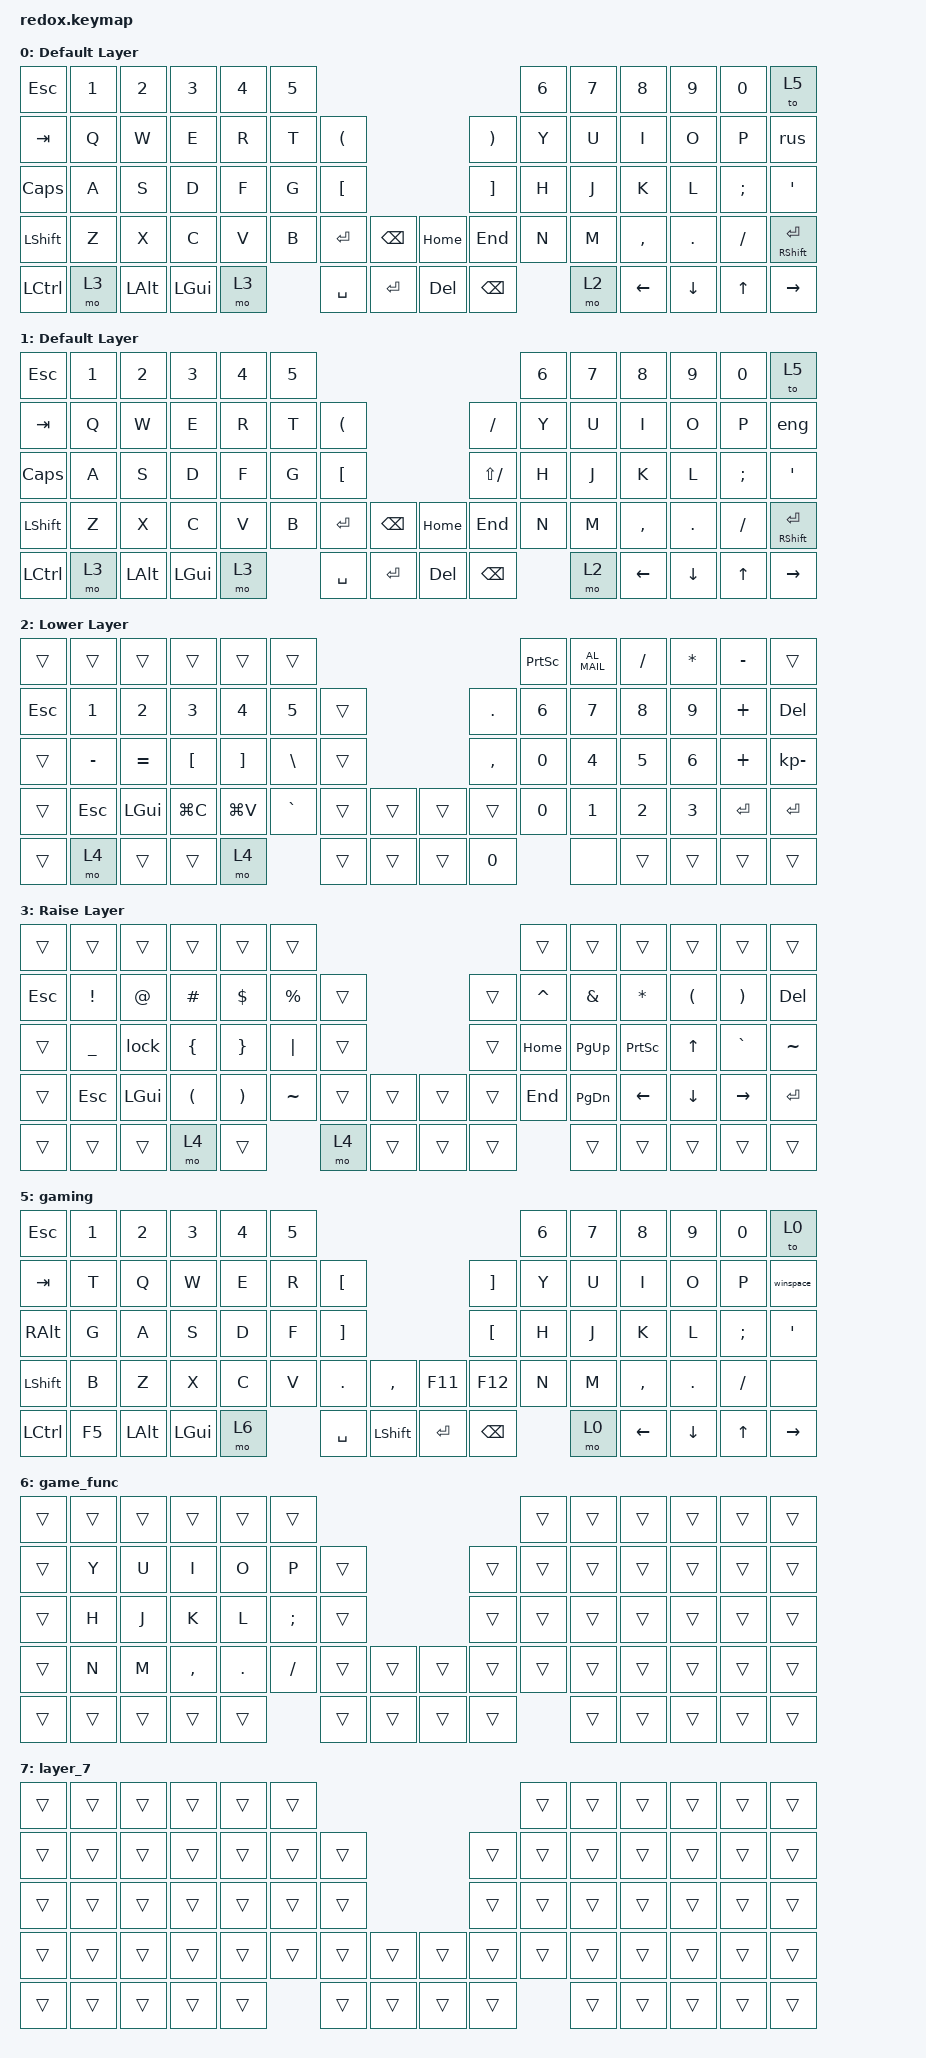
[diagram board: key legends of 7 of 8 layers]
/*
 * Copyright (c) 2021 The ZMK Contributors
 *
 * SPDX-License-Identifier: MIT
 */

#include <behaviors.dtsi>
#include <dt-bindings/zmk/bt.h>
#include <dt-bindings/zmk/keys.h>
#include <dt-bindings/zmk/outputs.h>

/ {
    sensors {
        compatible = "zmk,keymap-sensors";
        sensors = <&left_encoder &right_encoder>;
    };

    left_encoder: encoder_left {
        compatible = "alps,ec11";
        a-gpios = <&gpio1 1 (GPIO_ACTIVE_HIGH | GPIO_PULL_UP)>;
        b-gpios = <&gpio1 2 (GPIO_ACTIVE_HIGH | GPIO_PULL_UP)>;
        steps = <74>;
        status = "okay";
    };

    right_encoder: encoder_right {
        compatible = "alps,ec11";
        a-gpios = <&gpio0 24 (GPIO_ACTIVE_HIGH | GPIO_PULL_UP)>;
        b-gpios = <&gpio0 20 (GPIO_ACTIVE_HIGH | GPIO_PULL_UP)>;
        steps = <7>;
        status = "okay";
    };

    macros {
        rus: language {
            compatible = "zmk,behavior-macro";
            #binding-cells = <0>;
            bindings = <&kp LG(SPACE) &to 1>;
            label = "LANGUAGE";
        };

        eng: eng {
            compatible = "zmk,behavior-macro";
            #binding-cells = <0>;
            bindings = <&kp LG(SPACE) &to 0>;
            label = "ENG";
        };

        winspace: winspace {
            compatible = "zmk,behavior-macro";
            #binding-cells = <0>;
            bindings = <&kp LG(SPACE)>;
            label = "WINSPACE";
        };

        lock: lock {
            compatible = "zmk,behavior-macro";
            #binding-cells = <0>;
            bindings = <&kp LG(L)>;
            label = "LOCK";
        };
    };

    keymap {
        compatible = "zmk,keymap";

        layer_eng {
            display-name = "Default Layer";
            bindings = <
&kp ESC    &kp N1  &kp N2    &kp N3        &kp N4  &kp N5                                                       &kp N6  &kp N7  &kp N8     &kp N9    &kp N0    &to 5
&kp TAB    &kp Q   &kp W     &kp E         &kp R   &kp T   &kp LPAR                              &kp RPAR       &kp Y   &kp U   &kp I      &kp O     &kp P     &rus
&kp CAPS   &kp A   &kp S     &kp D         &kp F   &kp G   &kp LBKT                              &kp RBKT       &kp H   &kp J   &kp K      &kp L     &kp SEMI  &kp SQT
&kp LSHFT  &kp Z   &kp X     &kp C         &kp V   &kp B   &kp ENTER  &kp BACKSPACE    &kp HOME  &kp END        &kp N   &kp M   &kp COMMA  &kp DOT   &kp FSLH  &mt RSHFT RET
&kp LCTRL  &mo 3   &kp LALT  &kp LEFT_GUI  &mo 3           &kp SPACE  &kp ENTER        &kp DEL   &kp BACKSPACE          &mo 2   &kp LEFT   &kp DOWN  &kp UP    &kp RIGHT
            >;

            sensor-bindings = <
        &inc_dec_kp C_VOL_UP C_VOL_DN   // левый энкодер
        &inc_dec_kp G     &trans     // правый энкодер
            >;
        };

        layer_rus {
            display-name = "Default Layer";
            bindings = <
&kp ESC    &kp N1  &kp N2    &kp N3        &kp N4  &kp N5                                                       &kp N6  &kp N7  &kp N8     &kp N9    &kp N0    &to 5
&kp TAB    &kp Q   &kp W     &kp E         &kp R   &kp T   &kp LPAR                              &kp SLASH      &kp Y   &kp U   &kp I      &kp O     &kp P     &eng
&kp CAPS   &kp A   &kp S     &kp D         &kp F   &kp G   &kp LBKT                              &kp LS(SLASH)  &kp H   &kp J   &kp K      &kp L     &kp SEMI  &kp SQT
&kp LSHFT  &kp Z   &kp X     &kp C         &kp V   &kp B   &kp ENTER  &kp BACKSPACE    &kp HOME  &kp END        &kp N   &kp M   &kp COMMA  &kp DOT   &kp FSLH  &mt RSHFT RET
&kp LCTRL  &mo 3   &kp LALT  &kp LEFT_GUI  &mo 3           &kp SPACE  &kp ENTER        &kp DEL   &kp BACKSPACE          &mo 2   &kp LEFT   &kp DOWN  &kp UP    &kp RIGHT
            >;

            sensor-bindings =
                <&inc_dec_kp C_VOL_UP C_VOL_DN>,
                <&inc_dec_kp G>,
                <&trans>;
        };

        lower_layer {
            display-name = "Lower Layer";
            bindings = <
&trans   &trans     &trans     &trans     &trans     &trans                                          &kp PRINTSCREEN  &kp C_AL_MAIL  &kp FSLH  &kp STAR  &kp MINUS  &trans
&kp ESC  &kp N1     &kp N2     &kp N3     &kp N4     &kp N5     &trans                    &kp DOT    &kp N6           &kp N7         &kp N8    &kp N9    &kp PLUS   &kp DEL
&trans   &kp MINUS  &kp EQUAL  &kp LBKT   &kp RBKT   &kp BSLH   &trans                    &kp COMMA  &kp N0           &kp N4         &kp N5    &kp N6    &kp PLUS   &kp KP_MINUS
&trans   &kp ESC    &kp LGUI   &kp LG(C)  &kp LG(V)  &kp GRAVE  &trans  &trans    &trans  &trans     &kp N0           &kp N1         &kp N2    &kp N3    &kp RET    &kp RET
&trans   &mo 4      &trans     &trans     &mo 4                 &trans  &trans    &trans  &kp N0                      &none          &trans    &trans    &trans     &trans
            >;

            sensor-bindings = <&inc_dec_kp TAB LS(TAB)>;
        };

        raise_layer {
            display-name = "Raise Layer";
            bindings = <
&trans   &trans     &trans    &trans    &trans    &trans                                       &trans     &trans     &trans     &trans    &trans     &trans
&kp ESC  &kp EXCL   &kp AT    &kp HASH  &kp DLLR  &kp PRCNT  &trans                    &trans  &kp CARET  &kp AMPS   &kp ASTRK  &kp LPAR  &kp RPAR   &kp DEL
&trans   &kp UNDER  &lock     &kp LBRC  &kp RBRC  &kp PIPE   &trans                    &trans  &kp HOME   &kp PG_UP  &kp PSCRN  &kp UP    &kp GRAVE  &kp TILDE
&trans   &kp ESC    &kp LGUI  &kp LPAR  &kp RPAR  &kp TILDE  &trans  &trans    &trans  &trans  &kp END    &kp PG_DN  &kp LEFT   &kp DOWN  &kp RIGHT  &kp RET
&trans   &trans     &trans    &mo 4     &trans               &mo 4   &trans    &trans  &trans             &trans     &trans     &trans    &trans     &trans
            >;
        };

        adjust_layer {
            display-name = "Adjust Layer";
            bindings = <
&kp F1  &kp F2        &kp F3        &kp F4        &kp F5            &kp F6                                                    &kp F7        &kp F8        &kp F9        &kp F10       &kp F11       &to 5
&trans  &bt BT_SEL 0  &bt BT_SEL 1  &bt BT_SEL 2  &bt BT_SEL 3      &bt BT_SEL 4  &bootloader                    &bootloader  &bt BT_SEL 0  &bt BT_SEL 1  &bt BT_SEL 2  &bt BT_SEL 3  &bt BT_SEL 4  &out OUT_TOG
&trans  &kp K_MUTE    &kp C_VOL_DN  &kp C_VOL_UP  &kp C_PLAY_PAUSE  &none         &sys_reset                     &bt BT_CLR   &kp F1        &kp F2        &kp F3        &kp F4        &kp F5        &kp F6
&trans  &kp PSCRN     &kp PSCRN     &kp CAPS      &none             &none         &trans       &trans    &trans  &kp F7       &kp F8        &kp F9        &kp F10       &kp F11       &kp F12       &trans
&trans  &trans        &trans        &trans        &trans                          &trans       &trans    &trans  &trans                     &trans        &trans        &trans
            >;
        };

        gaming {
            bindings = <
&kp ESC    &kp N1  &kp N2    &kp N3    &kp N4  &kp N5                                                    &kp N6  &kp N7  &kp N8     &kp N9    &kp N0    &to 0
&kp TAB    &kp T   &kp Q     &kp W     &kp E   &kp R   &kp LBKT                           &kp RBKT       &kp Y   &kp U   &kp I      &kp O     &kp P     &winspace
&kp RALT   &kp G   &kp A     &kp S     &kp D   &kp F   &kp RBKT                           &kp LBKT       &kp H   &kp J   &kp K      &kp L     &kp SEMI  &kp APOS
&kp LSHFT  &kp B   &kp Z     &kp X     &kp C   &kp V   &kp DOT    &kp COMMA    &kp F11    &kp F12        &kp N   &kp M   &kp COMMA  &kp DOT   &kp FSLH  &none
&kp LCTRL  &kp F5  &kp LALT  &kp LGUI  &mo 6           &kp SPACE  &kp LSHFT    &kp ENTER  &kp BACKSPACE          &mo 0   &kp LEFT   &kp DOWN  &kp UP    &kp RIGHT
            >;
        };

        game_func {
            bindings = <
&trans  &trans  &trans  &trans     &trans   &trans                                      &trans  &trans  &trans  &trans  &trans  &trans
&trans  &kp Y   &kp U   &kp I      &kp O    &kp P     &trans                    &trans  &trans  &trans  &trans  &trans  &trans  &trans
&trans  &kp H   &kp J   &kp K      &kp L    &kp SEMI  &trans                    &trans  &trans  &trans  &trans  &trans  &trans  &trans
&trans  &kp N   &kp M   &kp COMMA  &kp DOT  &kp FSLH  &trans  &trans    &trans  &trans  &trans  &trans  &trans  &trans  &trans  &trans
&trans  &trans  &trans  &trans     &trans             &trans  &trans    &trans  &trans          &trans  &trans  &trans  &trans  &trans
            >;
        };

        layer_7 {
            bindings = <
&trans  &trans  &trans  &trans  &trans  &trans                                    &trans  &trans  &trans  &trans  &trans  &trans
&trans  &trans  &trans  &trans  &trans  &trans  &trans                    &trans  &trans  &trans  &trans  &trans  &trans  &trans
&trans  &trans  &trans  &trans  &trans  &trans  &trans                    &trans  &trans  &trans  &trans  &trans  &trans  &trans
&trans  &trans  &trans  &trans  &trans  &trans  &trans  &trans    &trans  &trans  &trans  &trans  &trans  &trans  &trans  &trans
&trans  &trans  &trans  &trans  &trans          &trans  &trans    &trans  &trans          &trans  &trans  &trans  &trans  &trans
            >;
        };
    };
};
